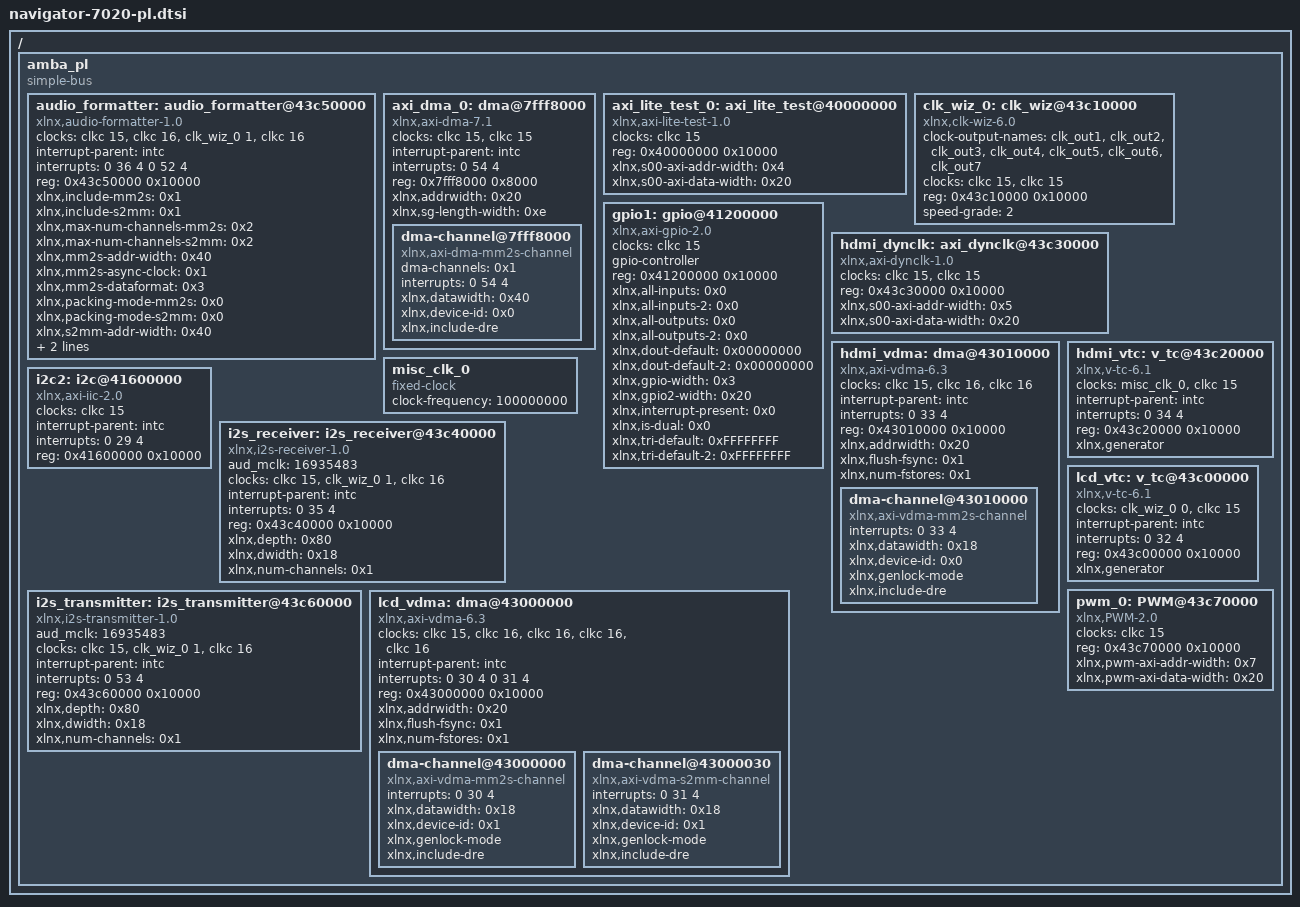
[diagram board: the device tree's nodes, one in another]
/*
 * CAUTION: This file is automatically generated by Xilinx.
 * Version: HSI 
 * Today is: Wed Sep  9 02:54:03 2020
 */


/ {
	amba_pl: amba_pl {
		#address-cells = <1>;
		#size-cells = <1>;
		compatible = "simple-bus";
		ranges ;
		audio_formatter: audio_formatter@43c50000 {
			clock-names = "s_axi_lite_aclk", "m_axis_mm2s_aclk", "aud_mclk", "s_axis_s2mm_aclk";
			clocks = <&clkc 15>, <&clkc 16>, <&clk_wiz_0 1>, <&clkc 16>;
			compatible = "xlnx,audio-formatter-1.0", "xlnx,audio-formatter-1.0";
			interrupt-names = "irq_mm2s", "irq_s2mm";
			interrupt-parent = <&intc>;
			interrupts = <0 36 4 0 52 4>;
			reg = <0x43c50000 0x10000>;
			xlnx,include-mm2s = <0x1>;
			xlnx,include-s2mm = <0x1>;
			xlnx,max-num-channels-mm2s = <0x2>;
			xlnx,max-num-channels-s2mm = <0x2>;
			xlnx,mm2s-addr-width = <0x40>;
			xlnx,mm2s-async-clock = <0x1>;
			xlnx,mm2s-dataformat = <0x3>;
			xlnx,packing-mode-mm2s = <0x0>;
			xlnx,packing-mode-s2mm = <0x0>;
			xlnx,s2mm-addr-width = <0x40>;
			xlnx,s2mm-async-clock = <0x1>;
			xlnx,s2mm-dataformat = <0x1>;
		};
		axi_dma_0: dma@7fff8000 {
			#dma-cells = <1>;
			clock-names = "s_axi_lite_aclk", "m_axi_mm2s_aclk";
			clocks = <&clkc 15>, <&clkc 15>;
			compatible = "xlnx,axi-dma-7.1", "xlnx,axi-dma-1.00.a";
			interrupt-names = "mm2s_introut";
			interrupt-parent = <&intc>;
			interrupts = <0 54 4>;
			reg = <0x7fff8000 0x8000>;
			xlnx,addrwidth = <0x20>;
			xlnx,sg-length-width = <0xe>;
			dma-channel@7fff8000 {
				compatible = "xlnx,axi-dma-mm2s-channel";
				dma-channels = <0x1>;
				interrupts = <0 54 4>;
				xlnx,datawidth = <0x40>;
				xlnx,device-id = <0x0>;
				xlnx,include-dre ;
			};
		};
		axi_lite_test_0: axi_lite_test@40000000 {
			clock-names = "s00_axi_aclk";
			clocks = <&clkc 15>;
			compatible = "xlnx,axi-lite-test-1.0";
			reg = <0x40000000 0x10000>;
			xlnx,s00-axi-addr-width = <0x4>;
			xlnx,s00-axi-data-width = <0x20>;
		};
		clk_wiz_0: clk_wiz@43c10000 {
			#clock-cells = <1>;
			clock-names = "s_axi_aclk", "clk_in1";
			clock-output-names = "clk_out1", "clk_out2", "clk_out3", "clk_out4", "clk_out5", "clk_out6", "clk_out7";
			clocks = <&clkc 15>, <&clkc 15>;
			compatible = "xlnx,clk-wiz-6.0", "xlnx,clocking-wizard";
			reg = <0x43c10000 0x10000>;
			speed-grade = <2>;
		};
		gpio1: gpio@41200000 {
			#gpio-cells = <3>;
			clock-names = "s_axi_aclk";
			clocks = <&clkc 15>;
			compatible = "xlnx,axi-gpio-2.0", "xlnx,xps-gpio-1.00.a";
			gpio-controller ;
			reg = <0x41200000 0x10000>;
			xlnx,all-inputs = <0x0>;
			xlnx,all-inputs-2 = <0x0>;
			xlnx,all-outputs = <0x0>;
			xlnx,all-outputs-2 = <0x0>;
			xlnx,dout-default = <0x00000000>;
			xlnx,dout-default-2 = <0x00000000>;
			xlnx,gpio-width = <0x3>;
			xlnx,gpio2-width = <0x20>;
			xlnx,interrupt-present = <0x0>;
			xlnx,is-dual = <0x0>;
			xlnx,tri-default = <0xFFFFFFFF>;
			xlnx,tri-default-2 = <0xFFFFFFFF>;
		};
		hdmi_dynclk: axi_dynclk@43c30000 {
			clock-names = "REF_CLK_I", "s00_axi_aclk";
			clocks = <&clkc 15>, <&clkc 15>;
			compatible = "xlnx,axi-dynclk-1.0";
			reg = <0x43c30000 0x10000>;
			xlnx,s00-axi-addr-width = <0x5>;
			xlnx,s00-axi-data-width = <0x20>;
		};
		hdmi_vdma: dma@43010000 {
			#dma-cells = <1>;
			clock-names = "s_axi_lite_aclk", "m_axi_mm2s_aclk", "m_axis_mm2s_aclk";
			clocks = <&clkc 15>, <&clkc 16>, <&clkc 16>;
			compatible = "xlnx,axi-vdma-6.3", "xlnx,axi-vdma-1.00.a";
			interrupt-names = "mm2s_introut";
			interrupt-parent = <&intc>;
			interrupts = <0 33 4>;
			reg = <0x43010000 0x10000>;
			xlnx,addrwidth = <0x20>;
			xlnx,flush-fsync = <0x1>;
			xlnx,num-fstores = <0x1>;
			dma-channel@43010000 {
				compatible = "xlnx,axi-vdma-mm2s-channel";
				interrupts = <0 33 4>;
				xlnx,datawidth = <0x18>;
				xlnx,device-id = <0x0>;
				xlnx,genlock-mode ;
				xlnx,include-dre ;
			};
		};
		hdmi_vtc: v_tc@43c20000 {
			clock-names = "clk", "s_axi_aclk";
			clocks = <&misc_clk_0>, <&clkc 15>;
			compatible = "xlnx,v-tc-6.1", "xlnx,v-tc-6.1";
			interrupt-names = "irq";
			interrupt-parent = <&intc>;
			interrupts = <0 34 4>;
			reg = <0x43c20000 0x10000>;
			xlnx,generator ;
		};
		misc_clk_0: misc_clk_0 {
			#clock-cells = <0>;
			clock-frequency = <100000000>;
			compatible = "fixed-clock";
		};
		i2c2: i2c@41600000 {
			#address-cells = <1>;
			#size-cells = <0>;
			clock-names = "s_axi_aclk";
			clocks = <&clkc 15>;
			compatible = "xlnx,axi-iic-2.0", "xlnx,xps-iic-2.00.a";
			interrupt-names = "iic2intc_irpt";
			interrupt-parent = <&intc>;
			interrupts = <0 29 4>;
			reg = <0x41600000 0x10000>;
		};
		i2s_receiver: i2s_receiver@43c40000 {
			aud_mclk = <16935483>;
			clock-names = "s_axi_ctrl_aclk", "aud_mclk", "m_axis_aud_aclk";
			clocks = <&clkc 15>, <&clk_wiz_0 1>, <&clkc 16>;
			compatible = "xlnx,i2s-receiver-1.0", "xlnx,i2s-receiver-1.0";
			interrupt-names = "irq";
			interrupt-parent = <&intc>;
			interrupts = <0 35 4>;
			reg = <0x43c40000 0x10000>;
			xlnx,depth = <0x80>;
			xlnx,dwidth = <0x18>;
			xlnx,num-channels = <0x1>;
		};
		i2s_transmitter: i2s_transmitter@43c60000 {
			aud_mclk = <16935483>;
			clock-names = "s_axi_ctrl_aclk", "aud_mclk", "s_axis_aud_aclk";
			clocks = <&clkc 15>, <&clk_wiz_0 1>, <&clkc 16>;
			compatible = "xlnx,i2s-transmitter-1.0", "xlnx,i2s-transmitter-1.0";
			interrupt-names = "irq";
			interrupt-parent = <&intc>;
			interrupts = <0 53 4>;
			reg = <0x43c60000 0x10000>;
			xlnx,depth = <0x80>;
			xlnx,dwidth = <0x18>;
			xlnx,num-channels = <0x1>;
		};
		lcd_vdma: dma@43000000 {
			#dma-cells = <1>;
			clock-names = "s_axi_lite_aclk", "m_axi_mm2s_aclk", "m_axis_mm2s_aclk", "m_axi_s2mm_aclk", "s_axis_s2mm_aclk";
			clocks = <&clkc 15>, <&clkc 16>, <&clkc 16>, <&clkc 16>, <&clkc 16>;
			compatible = "xlnx,axi-vdma-6.3", "xlnx,axi-vdma-1.00.a";
			interrupt-names = "mm2s_introut", "s2mm_introut";
			interrupt-parent = <&intc>;
			interrupts = <0 30 4 0 31 4>;
			reg = <0x43000000 0x10000>;
			xlnx,addrwidth = <0x20>;
			xlnx,flush-fsync = <0x1>;
			xlnx,num-fstores = <0x1>;
			dma-channel@43000000 {
				compatible = "xlnx,axi-vdma-mm2s-channel";
				interrupts = <0 30 4>;
				xlnx,datawidth = <0x18>;
				xlnx,device-id = <0x1>;
				xlnx,genlock-mode ;
				xlnx,include-dre ;
			};
			dma-channel@43000030 {
				compatible = "xlnx,axi-vdma-s2mm-channel";
				interrupts = <0 31 4>;
				xlnx,datawidth = <0x18>;
				xlnx,device-id = <0x1>;
				xlnx,genlock-mode ;
				xlnx,include-dre ;
			};
		};
		lcd_vtc: v_tc@43c00000 {
			clock-names = "clk", "s_axi_aclk";
			clocks = <&clk_wiz_0 0>, <&clkc 15>;
			compatible = "xlnx,v-tc-6.1", "xlnx,v-tc-6.1";
			interrupt-names = "irq";
			interrupt-parent = <&intc>;
			interrupts = <0 32 4>;
			reg = <0x43c00000 0x10000>;
			xlnx,generator ;
		};
		pwm_0: PWM@43c70000 {
			clock-names = "pwm_axi_aclk";
			clocks = <&clkc 15>;
			compatible = "xlnx,PWM-2.0";
			reg = <0x43c70000 0x10000>;
			xlnx,pwm-axi-addr-width = <0x7>;
			xlnx,pwm-axi-data-width = <0x20>;
		};
	};
};
